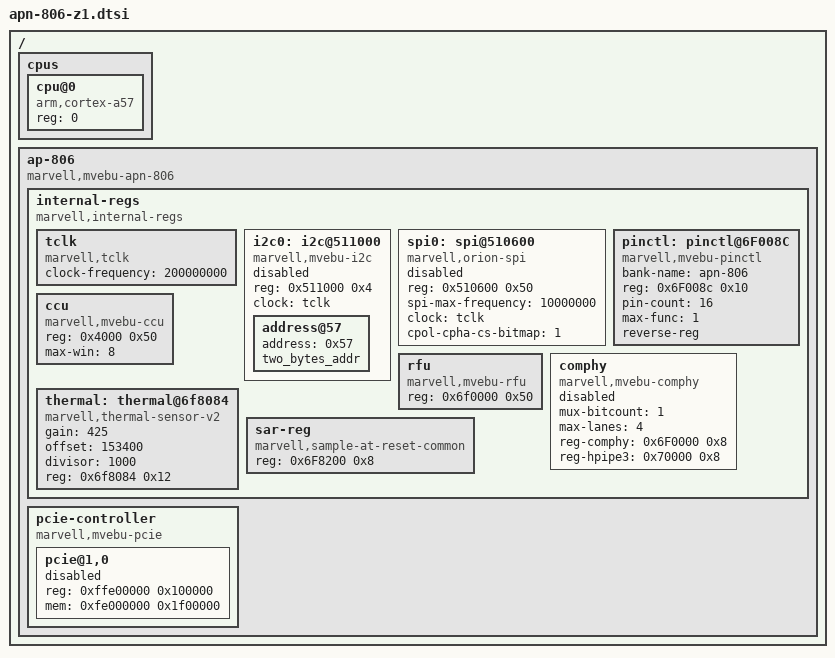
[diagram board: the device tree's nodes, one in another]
/*
 * ***************************************************************************
 * Copyright (C) 2015 Marvell International Ltd.
 * ***************************************************************************
 * This program is free software: you can redistribute it and/or modify it
 * under the terms of the GNU General Public License as published by the Free
 * Software Foundation, either version 2 of the License, or any later version.
 *
 * This program is distributed in the hope that it will be useful,
 * but WITHOUT ANY WARRANTY; without even the implied warranty of
 * MERCHANTABILITY or FITNESS FOR A PARTICULAR PURPOSE.  See the
 * GNU General Public License for more details.
 *
 * You should have received a copy of the GNU General Public License
 * along with this program.  If not, see <http://www.gnu.org/licenses/>.
 * ***************************************************************************
 */

#include <dt-bindings/comphy/comphy_data.h>
/ {

	#address-cells = <2>;
	#size-cells = <2>;

	cpus {
		#address-cells = <1>;
		#size-cells = <0>;
		cpu@0 {
			device_type = "cpu";
			compatible = "arm,cortex-a57";
			reg = <0>;
		};
	};

	ap-806 {
		compatible = "marvell,mvebu-apn-806";
		#address-cells = <1>;
		#size-cells = <0>;

		internal-regs {
			compatible = "marvell,internal-regs";
			#address-cells = <1>;
			#size-cells = <1>;
			ranges = <0x0000 0xf0000000 0x1000000>;

			tclk: tclk {
				compatible = "marvell,tclk";
				#clock-cells = <0>;
				clock-frequency = <200000000>;
			};

			i2c0: i2c@511000 {
				compatible = "marvell,mvebu-i2c";
				reg = <0x511000 0x4>;
				clock = <&tclk>;
				status = "disable";
				address@57 {
					address = <0x57>;
					two_bytes_addr;
				};
			};

			spi0: spi@510600 {
				compatible = "marvell,orion-spi";
				reg = <0x510600 0x50>;
				spi-max-frequency = <10000000>;
				clock = <&tclk>;
				cpol-cpha-cs-bitmap = <1>; /* bit i is set if the CPOL and CPHA
							      of CS-i is enabled or not */
				status = "disable";
			};

			pinctl: pinctl@6F008C {
				compatible = "marvell,mvebu-pinctl";
				bank-name ="apn-806";
				reg = <0x6F008c 0x10>;
				pin-count = <16>;
				max-func = <1>;
				reverse-reg;
			};

			ccu {
				compatible = "marvell,mvebu-ccu";
				reg = <0x4000 0x50>;
				max-win = <8>;
			};

			rfu {
				compatible = "marvell,mvebu-rfu";
				reg = <0x6f0000 0x50>;
			};

			comphy {
				compatible = "marvell,mvebu-comphy", "marvell,comphy-ap806";
				mux-bitcount = <1>;
				max-lanes = <4>;
				reg-comphy = <0x6F0000 0x8>;
				reg-hpipe3 = <0x70000 0x8>;
				status = "disabled";
			};

			thermal: thermal@6f8084 {
				compatible = "marvell,thermal-sensor-v2";
				gain = <425>;
				offset = <153400>;
				divisor = <1000>;
				reg = <0x6f8084 0x12>;
				status = "okay";
			};

			sar-reg {
				compatible = "marvell,sample-at-reset-common", "marvell,sample-at-reset-ap806";
				reg = <0x6F8200 0x8>;
			};
		};

		pcie-controller {
			#address-cells = <1>;
			#size-cells = <1>;
			compatible = "marvell,mvebu-pcie";

			pcie@1,0 {
				reg = <0xffe00000 0x100000>;
				mem = <0xfe000000 0x1f00000>;
				status = "disable";
			};
		};
	};
};
